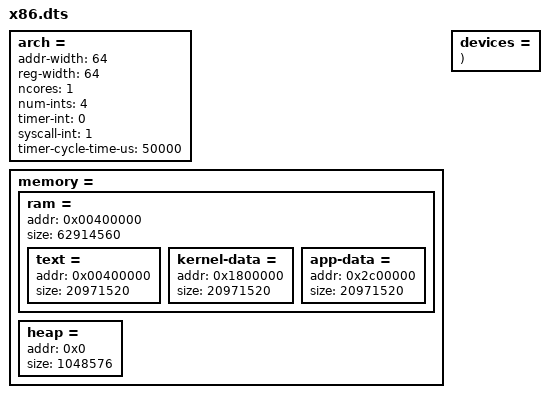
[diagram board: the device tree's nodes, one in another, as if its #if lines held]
/**
 * Copyright (C) 2020 Jan Nowotsch
 * Author Jan Nowotsch	<jan.nowotsch@gmail.com>
 *
 * Released under the terms of the GNU GPL v2.0
 */



#include <config/config.h>
#include <bridge.dts>
#include <gpio.dts>
#include <loop.dts>
#include <term.dts>
#include <x11.dts>
#include <x86.dts>
#include "common/i2cdemo.dts"
#include "common/looptty.dts"
#include "common/loopvram.dts"
#include "common/tty.dts"
#include "common/vramdemo.dts"


arch = {
	addr-width = 64;
	reg-width = 64;

	ncores = 1;

	// interrupts
	num-ints = 4;

	timer-int = 0;
	syscall-int = 1;

	timer-cycle-time-us = 50000;
};

memory = {
	ram = {
		addr = 0x00400000;
		size = 62914560;

		text = {
			addr = 0x00400000;
			size = 20971520;
		};

		kernel-data = {
			addr = 0x1800000;
			size = 20971520;
		};

		app-data = {
			addr = 0x2c00000;
			size = 20971520;
		};
	};

	// The heap needs to be allocated dynamically to allow
	// using it as shared memory. However, a heap node is
	// needed since the kernel assumes its presence.
	heap = {
		addr = 0x0;
		size = 1048576;
	};
};

devices = {
	x86_uart(
		0,				// uart name
		"/dev/stdin",	// path
		3,				// rx interrupt
		0,				// tx interrupt
		115200,			// baudrate
		0,				// stop bits (1)
		0,				// parity (UART_PARITY_NONE)
		3,				// csize (UART_CS_8)

		tty_user(
			0,	// term name
			0	// tty name
		);
	);

#ifdef CONFIG_LOOP_BLOCK
	loop(
		0,	// loop name
		32	// buffer size
	);
#endif // CONFIG_LOOP_BLOCK

#ifdef CONFIG_LOOP_TERM
	tty_loop(
		0,		// loop name
		1,		// term name
		loop0	// tty name
	);
#endif // CONFIG_LOOP_TERM

#ifdef CONFIG_LOOP_VRAM
	vram_loop(
		0,		// loop name
		0,		// vram name
		2,		// term name
		vram0	// tty name
	);
#endif // CONFIG_LOOP_VRAM

#ifdef CONFIG_DRIVER_X11
	x11_dsp(
		x11,	// display name
		3,		// scale

		vram_demo(
			x11,	// vram name
			3,		// term name
			x11,	// tty name
			128,	// width
			64		// height
		);
	);
#endif // CONFIG_DRIVER_X11

#ifdef CONFIG_DRIVER_GPIO
	x86_gpio(
		0,	// gpio name
		0,	// interrupt timer period [ms]

		gpio(
			0,		// gpio name
			0xff,	// in mask
			0xff,	// out mask
			0x00,	// int mask
			0x00,	// invert mask
			0,		// interrupt

			gpio_port(
				0,		// gpio name
				0, 		// port name
				0xff,	// in mask
				0xff,	// out mask
				0x00	// int mask
			);
		);
	);

# ifdef CONFIG_INIT_TEST
	x86_gpio(
		1,	// gpio name
		10,	// interrupt timer period [ms]

		gpio(
			1,					// gpio name
			0xffffffff,			// in mask
			0xffffffff,			// out mask
			0xffffffff,			// int mask
			0x000005f5,			// invert mask
			(arch.num-ints++),	// interrupt

			gpio_port(
				1,		// gpio name
				0,		// port name
				0xff0f,	// in mask
				0xff00,	// out mask
				0x000f	// int mask
			);

			gpio_pin(
				1,		// gpio name
				0,		// pin name
				4,		// pin
				0x3		// mode (i/o)
			);

			gpio_port(
				1,				// gpio name
				int0,			// port name
				0xffffffff,		// in mask
				0xffffffff,		// out mask
				0xffffffff		// int mask
			);
		);
	);
# endif // CONFIG_INIT_TEST
#endif // CONFIG_DRIVER_GPIO

#ifdef CONFIG_DRIVER_BRIDGE
	x86_uart(
		1,				// uart name
		"/dev/ttyUSB1",	// path
		0,				// rx interrupt
		0,				// tx interrupt
		115200,			// baudrate
		0,				// stop bits (1)
		0,				// parity (UART_PARITY_NONE)
		3,				// csize (UART_CS_8)

		bridge_uart_itf(
			0uarti,		// bridge name
			0,			// id
			2,			// chunksize
			0,			// rx interrupt
			0			// tx interrupt
		);
	);

# ifdef CONFIG_BRIDGE_UART_DEV
	bridge(
		0uart,				// bridge name
		0,					// id
		2,					// chunksize
		(arch.num-ints++),	// rx interrupt
		(arch.num-ints++),	// tx interrupt

		bridge_uart_dev(
			3,			// uart name

			term(
				4, 		// term name
				0x0,	// iflags (none)
				0x0,	// oflags (none)
				0x0,	// lflags (none)
				0,		// tabs

				tty(
					brdg0	// tty name
				);
			);
		);
	);
# endif // CONFIG_BRIDGE_UART_DEV

# ifdef CONFIG_BRIDGE_I2C_DEV
	bridge(
		0i2c,	// bridge name
		0,		// id
		2,		// chunksize
		0,		// rx interrupt
		0,		// tx interrupt

		bridge_i2c_dev(
			0,	// bridge name
			0,	// clk_khz
			17,	// addr

			i2c_demo_devices(
				0,		// i2craw name
				0,		// envsensor name
				mcp,	// mcp23017 name
				i2c		// display name
			);
		);
	);
# endif // CONFIG_BRIDGE_I2C_DEV
#endif // CONFIG_DRIVER_BRIDGE
};
